# CY8C5888LTI_LP097 register map
File version: 0.1
CY8C58LP
Registers are 32-bit, read-write, no defined reset value unless marked. A register's access mark holds for its fields unless they carry their own. Offsets are from the block's base; lines under a group give offsets from that group; [hi:lo] are bit positions; {n}, {i} and the like mark numbered series; 'fields as' and 'values as' point back to an identical list; <NAME> marks a mode.

## Memory map
0x00000000 CAN
0x00000000 Timer
0x00000000 ADC_SAR_1 — SAR ADC
0x00000000 UART_1 — UART

## CAN
Base 0x00000000
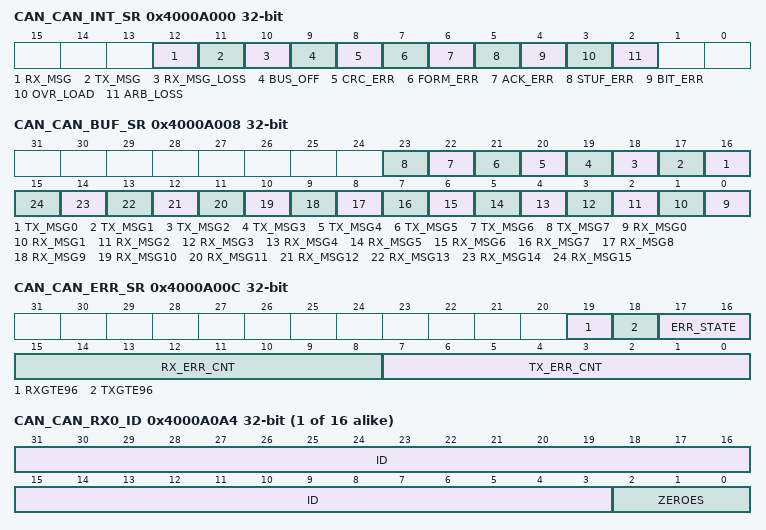
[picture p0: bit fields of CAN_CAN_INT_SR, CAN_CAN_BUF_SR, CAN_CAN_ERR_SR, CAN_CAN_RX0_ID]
0x4000A000 CAN_CAN_INT_SR — The interrupt status register stores internal interrupt events. ? Once a bit is set it remains set until it is cleared by writing a '1' to it. ? The interrupt enable register has no effect on the interrupt status register. ? A pending interrupt occurs when the flag is set to '1'. To acknowledge an interrupt, set the flag to '1'
  [12] RX_MSG — Msg Recieved
  [11] TX_MSG — Tx msg Sent
  [10] RX_MSG_LOSS — Rx msg loss Interrupt
  [9] BUS_OFF — Bus Off State
  [8] CRC_ERR — CRC Error Interrupt
  [7] FORM_ERR — Form Error Interrupt
  [6] ACK_ERR — Ack Error Interrupt
  [5] STUF_ERR — Stuff Error Interrupt
  [4] BIT_ERR — Bit Error Interrupt
  [3] OVR_LOAD — Overload Interrupt
  [2] ARB_LOSS — Arbitration Loss
0x4000A008 CAN_CAN_BUF_SR — These status indicators bundle the respective flags from all RxMessage and TxMessage buffers. ? Note All flags are read only. To acknowledge a MsgAv flag, the CPU must write to the respective RxMessage buffer
  [n+16] TX_MSG{n} (n=0..7) — Tx req Pending for Tx Msg{n}
  [n] RX_MSG{n} (n=0..15) — Rx Msg{n} Available
0x4000A00C CAN_CAN_ERR_SR — Status indicators are provided to report the CAN controller error state, receive error count, and transmit error count. ? Special flags report error counter values equal to or in excess of 96 errors are available to indicate heavily disturbed bus situations. ? The transmitter error counter according to the CAN standard. When it is greater than 255 Decimal, it is fixed at 255 Decimal.
  [19] RXGTE96 — Rx Error Count is greater or equal to 96 Decimal
  [18] TXGTE96 — Tx Error Count is greater or equal to 96 Decimal
  [17:16] ERR_STATE — Error State of CAN node, 00 error active, 01 error passive, 1x bus off
  [15:8] RX_ERR_CNT — Rx error Count. When in bus-off state,this counter is used to count 128 groups of 11 recessive bits
  [7:0] TX_ERR_CNT — Tx error Count
{0x4000A024+0x10*i} CAN_CAN_TX{i}_ID (i=0..7) — CAN Tx Msg Identifier
  [31:3] ID — Tx Msg Indentifier
{0x4000A028+0x10*i} CAN_CAN_TX{i}_DH (i=0..7) — CAN Tx Msg Upper Data Bytes
  [31:0] DATA_HIGH — Upper Data Bytes
{0x4000A02C+0x10*i} CAN_CAN_TX{i}_DL (i=0..7) — CAN Tx Msg Lower Data Bytes
  [31:0] DATA_LOW — Lower Data Bytes
{0x4000A0A4+0x20*i} CAN_CAN_RX{i}_ID (i=0..15) — The register contains Rx Msg Identifier
  [31:3] ID — Rx Msg Indentifier
  [2:0] ZEROES — zeros
{0x4000A0A8+0x20*i} CAN_CAN_RX{i}_DH (i=0..15) — The register contains the Rx Msg Upper Data Bytes
  [31:0] DATA_HIGH — Upper Data Bytes
{0x4000A0AC+0x20*i} CAN_CAN_RX{i}_DL (i=0..15) — The register contains the Rx Msg Lover Data Bytes
  [31:0] DATA_LOW — Lower Data Bytes

## Timer
Base 0x00000000
0x400043A3 Timer_GLOBAL_ENABLE 8-bit — PM.ACT.CFG
  [3:0] en_timer — Enable timer/counters.
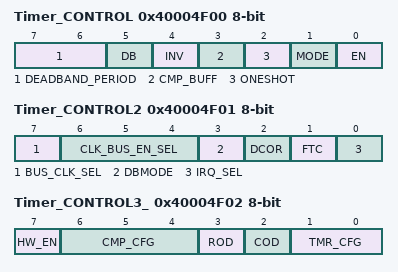
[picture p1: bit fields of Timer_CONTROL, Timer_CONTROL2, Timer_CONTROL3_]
0x40004F00 Timer_CONTROL 8-bit — TMRx.CFG0
  [7:6] DEADBAND_PERIOD
  [5] DB — Deadband mode--Deadband phases phi1 and phi2 are outputted on CMP and TC output pins respectively.
    0=Timer (CMP and TC are output.); 1=Deadband (PHI1 (instead of CMP) and PHI2 (instead of TC) are output.)
  [4] INV — Invert sense of TIMEREN signal
  [3] CMP_BUFF — Buffer compare register. Compare register updates only on timer terminal count.
  [2] ONESHOT — Timer stops upon reaching stop condition defined by TMR_CFG bits. Can be restarted by asserting TIMER RESET or disabling and re-enabling block.
  [1] MODE — Mode. (0 = Timer; 1 = Comparator)
    0=Timer mode. CNT/CMP register holds timer count value.; 1=Comparator mode. CNT/CMP register holds comparator threshold value.
  [0] EN — Enables timer/comparator.
0x40004F01 Timer_CONTROL2 8-bit — TMRx.CFG1
  [7] BUS_CLK_SEL — Bus Clock selection.
  [6:4] CLK_BUS_EN_SEL — Digital Global Clock selection.
  [3] DBMODE — Deadband mode (asynchronous/synchronous). CMP output pin is also affected when not in deadband mode (CFG0.DEADBAND).
  [2] DCOR — Disable Clear on Read (DCOR) of Status Register SR0.
  [1] FTC — First Terminal Count (FTC). Setting this bit forces a single pulse on the TC pin when first enabled.
    0=Disable_FTC (Disable the single cycle pulse, which signifies the timer is starting.); 1=Enable_FTC (Enable the single cycle pulse, which signifies the timer is starting.)
  [0] IRQ_SEL — Irq selection. (0 = raw interrupts; 1 = status register interrupts)
0x40004F02 Timer_CONTROL3_ 8-bit — TMRx.CFG2
  [7] HW_EN — When set Timer Enable controls counting.
  [6:4] CMP_CFG — Comparator configurations
    0=Equal (Compare Equal); 1=Less_than (Compare Less Than); 2=Less_than_or_equal (Compare Less Than or Equal .); 3=Greater (Compare Greater Than .); 4=Greater_than_or_equal (Compare Greater Than or Equal)
  [3] ROD — Reset On Disable (ROD). Resets internal state of output logic
  [2] COD — Clear On Disable (COD). Clears or gates outputs to zero.
  [1:0] TMR_CFG — Timer configuration (MODE = 0): 000 = Continuous; 001 = Pulsewidth; 010 = Period; 011 = Stop on IRQ
    0=Continuous (Timer runs while EN bit of CFG0 register is set to '1'.); 1=Pulsewidth (Timer runs from positive to negative edge of TIMEREN.); 2=Period (Timer runs from positive to positive edge of TIMEREN.); 3=Irq (Timer runs until IRQ.)
0x40004F04 Timer_PERIOD 8-bit — TMRx.PER0 - Assigned Period
0x40004F06 Timer_COUNTER 8-bit — TMRx.CNT_CMP0 - Current Down Counter Value

## ADC_SAR_1 — SAR ADC
Base 0x00000000
0x40004616 SAR_TR0 8-bit — SAR trim register
{0x40005908+i} SAR_CSR{i} 8-bit (i=0..6) — SAR status and control register {i}
0x40005B28 SAR_SW0 8-bit — SAR Analog Routing Register 0
{0x40005B28+i} SAR_SW{i} 8-bit (i=2..4) — SAR Analog Routing Register {i}
0x40005B2E SAR_SW6 8-bit — SAR Analog Routing Register 6
0x40005B2F SAR_CLK 8-bit — SAR Clock Selection Register
0x40005BA2 SAR_WRK 16-bit — SAR working register

## UART_1 — UART
Base 0x00000000
0x40006528 RX_UART_1_RX_ADDRESS1 8-bit — RX Address1 Register
0x40006538 RX_UART_1_RX_ADDRESS2 8-bit — RX Address2 Register
0x40006548 RX_UART_1_RX_DATA 8-bit — RX Data Register
0x4000654A TX_UART_1_TX_DATA 8-bit — TX Data Register
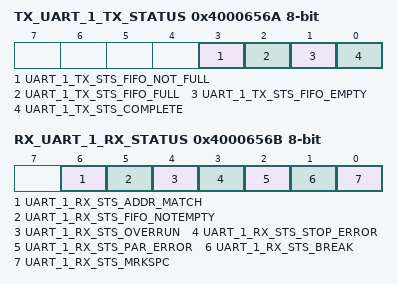
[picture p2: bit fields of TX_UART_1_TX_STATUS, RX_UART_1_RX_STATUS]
0x4000656A TX_UART_1_TX_STATUS 8-bit — TX status register
  [3] UART_1_TX_STS_FIFO_NOT_FULL ro, [2] UART_1_TX_STS_FIFO_FULL ro, [1] UART_1_TX_STS_FIFO_EMPTY ro, [0] UART_1_TX_STS_COMPLETE ro
0x4000656B RX_UART_1_RX_STATUS 8-bit — RX status register
  [6] UART_1_RX_STS_ADDR_MATCH ro, [5] UART_1_RX_STS_FIFO_NOTEMPTY ro, [4] UART_1_RX_STS_OVERRUN ro, [3] UART_1_RX_STS_STOP_ERROR ro, [2] UART_1_RX_STS_PAR_ERROR ro, [1] UART_1_RX_STS_BREAK ro, [0] UART_1_RX_STS_MRKSPC ro
